# STM32F446 register map
File version: 1.1
CPU: CM4 r1p0, little endian, no MPU, no FPU, 3 interrupt priority bits
Registers are 32-bit, read-write, reset 0x0 unless marked. A register's access mark holds for its fields unless they carry their own. Offsets are from the block's base; [hi:lo] are bit positions.

## QUADSPI — QuadSPI interface
Base 0xA0001000
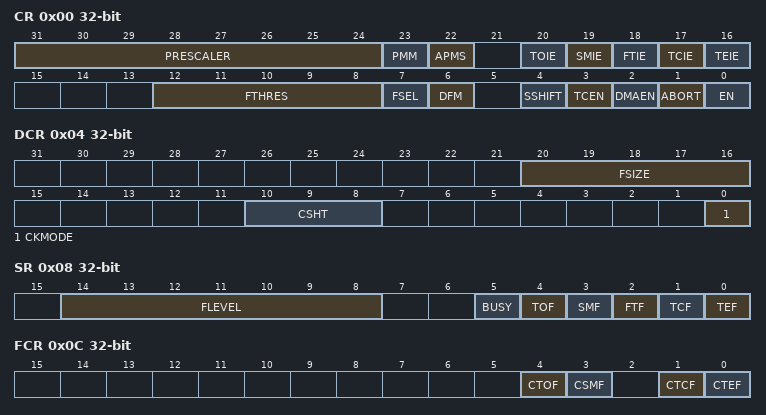
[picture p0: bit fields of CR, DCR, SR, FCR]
0x00 CR — control register
  [31:24] PRESCALER — Clock prescaler
  [23] PMM — Polling match mode
  [22] APMS — Automatic poll mode stop
  [20] TOIE — TimeOut interrupt enable
  [19] SMIE — Status match interrupt enable
  [18] FTIE — FIFO threshold interrupt enable
  [17] TCIE — Transfer complete interrupt enable
  [16] TEIE — Transfer error interrupt enable
  [12:8] FTHRES — IFO threshold level
  [7] FSEL — FLASH memory selection
  [6] DFM — Dual-flash mode
  [4] SSHIFT — Sample shift
  [3] TCEN — Timeout counter enable
  [2] DMAEN — DMA enable
  [1] ABORT — Abort request
  [0] EN — Enable
0x04 DCR — device configuration register
  [20:16] FSIZE — FLASH memory size
  [10:8] CSHT — Chip select high time
  [0] CKMODE — Mode 0 / mode 3
0x08 SR ro — status register
  [14:8] FLEVEL — FIFO level
  [5] BUSY
  [4] TOF — Timeout flag
  [3] SMF — Status match flag
  [2] FTF — FIFO threshold flag
  [1] TCF — Transfer complete flag
  [0] TEF — Transfer error flag
0x0C FCR — flag clear register
  [4] CTOF — Clear timeout flag
  [3] CSMF — Clear status match flag
  [1] CTCF — Clear transfer complete flag
  [0] CTEF — Clear transfer error flag
0x10 DLR — data length register
  [31:0] DL — Data length
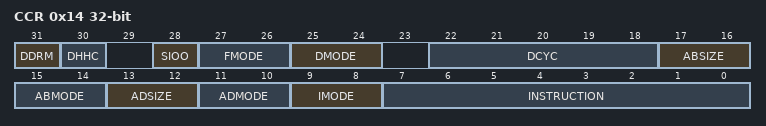
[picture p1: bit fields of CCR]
0x14 CCR — communication configuration register
  [31] DDRM — Double data rate mode
  [30] DHHC — DDR hold half cycle
  [28] SIOO — Send instruction only once mode
  [27:26] FMODE — Functional mode
  [25:24] DMODE — Data mode
  [22:18] DCYC — Number of dummy cycles
  [17:16] ABSIZE — Alternate bytes size
  [15:14] ABMODE — Alternate bytes mode
  [13:12] ADSIZE — Address size
  [11:10] ADMODE — Address mode
  [9:8] IMODE — Instruction mode
  [7:0] INSTRUCTION
0x18 AR — address register
  [31:0] ADDRESS
0x1C ABR
  [31:0] ALTERNATE
0x20 DR — data register
  [31:0] DATA
0x24 PSMKR — polling status mask register
  [31:0] MASK — Status mask
0x28 PSMAR — polling status match register
  [31:0] MATCH — Status match
0x2C PIR — polling interval register
  [15:0] INTERVAL — Polling interval
0x30 LPTR — low-power timeout register
  [15:0] TIMEOUT — Timeout period

## SPDIF_RX — Receiver Interface
Base 0x40004000
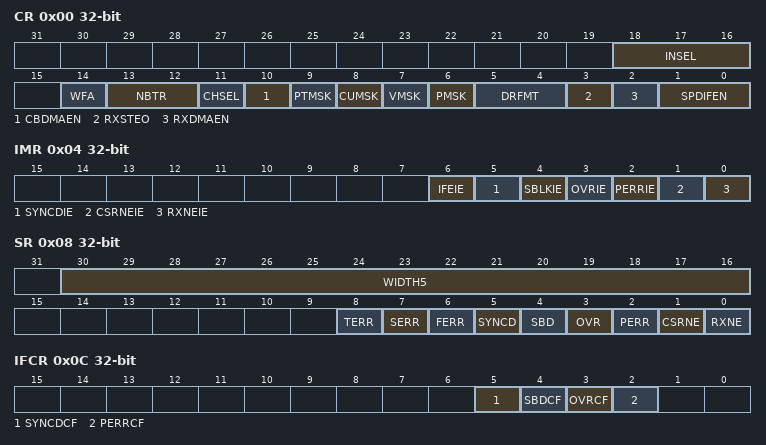
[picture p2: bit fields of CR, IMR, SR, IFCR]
0x00 CR — Control register
  [18:16] INSEL — input selection
  [14] WFA — Wait For Activity
  [13:12] NBTR — Maximum allowed re-tries during synchronization phase
  [11] CHSEL — Channel Selection
  [10] CBDMAEN — Control Buffer DMA ENable for control flow
  [9] PTMSK — Mask of Preamble Type bits
  [8] CUMSK — Mask of channel status and user bits
  [7] VMSK — Mask of Validity bit
  [6] PMSK — Mask Parity error bit
  [5:4] DRFMT — RX Data format
  [3] RXSTEO — STerEO Mode
  [2] RXDMAEN — Receiver DMA ENable for data flow
  [1:0] SPDIFEN — Peripheral Block Enable
0x04 IMR — Interrupt mask register
  [6] IFEIE — Serial Interface Error Interrupt Enable
  [5] SYNCDIE — Synchronization Done
  [4] SBLKIE — Synchronization Block Detected Interrupt Enable
  [3] OVRIE — Overrun error Interrupt Enable
  [2] PERRIE — Parity error interrupt enable
  [1] CSRNEIE — Control Buffer Ready Interrupt Enable
  [0] RXNEIE — RXNE interrupt enable
0x08 SR ro — Status register
  [30:16] WIDTH5 — Duration of 5 symbols counted with SPDIF_CLK
  [8] TERR — Time-out error
  [7] SERR — Synchronization error
  [6] FERR — Framing error
  [5] SYNCD — Synchronization Done
  [4] SBD — Synchronization Block Detected
  [3] OVR — Overrun error
  [2] PERR — Parity error
  [1] CSRNE — Control Buffer register is not empty
  [0] RXNE — Read data register not empty
0x0C IFCR wo — Interrupt Flag Clear register
  [5] SYNCDCF — Clears the Synchronization Done flag
  [4] SBDCF — Clears the Synchronization Block Detected flag
  [3] OVRCF — Clears the Overrun error flag
  [2] PERRCF — Clears the Parity error flag
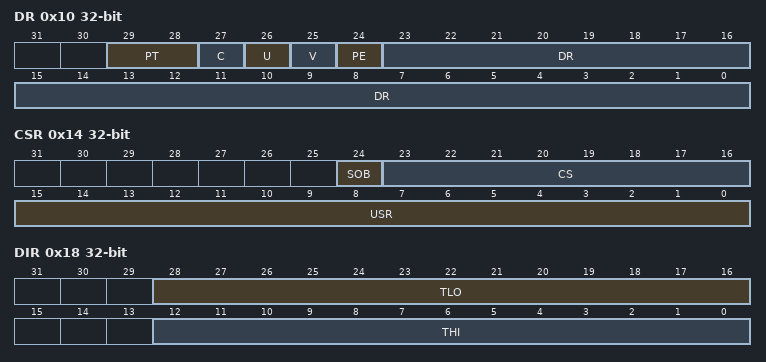
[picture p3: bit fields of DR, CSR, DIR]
0x10 DR ro — Data input register
  [29:28] PT — Preamble Type
  [27] C — Channel Status bit
  [26] U — User bit
  [25] V — Validity bit
  [24] PE — Parity Error bit
  [23:0] DR — Parity Error bit
0x14 CSR ro — Channel Status register
  [24] SOB — Start Of Block
  [23:16] CS — Channel A status information
  [15:0] USR — User data information
0x18 DIR ro — Debug Information register
  [28:16] TLO — Threshold LOW
  [12:0] THI — Threshold HIGH
